# GD32E51x_HD register map
File version: 1.0
CPU: CM33 r0p4, little endian, MPU, FPU, 4 interrupt priority bits
Registers are 32-bit, read-write, reset 0x0 unless marked. A register's access mark holds for its fields unless they carry their own. Offsets are from the block's base; [hi:lo] are bit positions; {n}, {i} and the like mark numbered series.

## TMU
Base 0x40080000
0x00 IDATA0 reset 0x3F800000 — Input data0 register
0x04 IDATA1 reset 0x3F800000 — Input data1 register
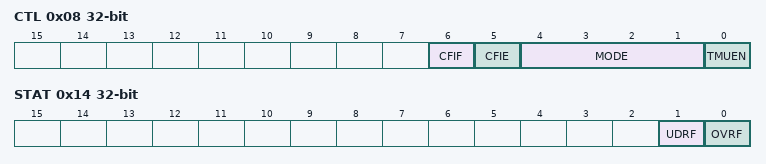
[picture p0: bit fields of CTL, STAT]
0x08 CTL access per field — Control register
  [6] CFIF ro
  [5] CFIE rw
  [4:1] MODE rw — Set the mode of TMU
  [0] TMUEN rw — start TMU module calculation
0x0C DATA0 reset 0x34000000
0x10 DATA1
0x14 STAT ro — Status register
  [1] UDRF — The flag of underflow
  [0] OVRF — The flag of overflow

## WWDGT — Window watchdog timer
Base 0x40002C00
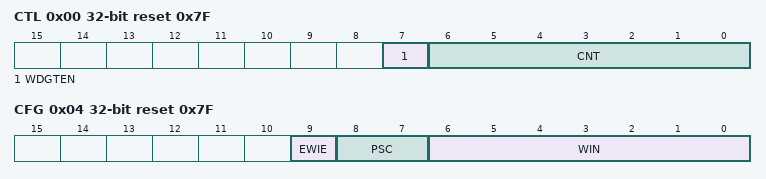
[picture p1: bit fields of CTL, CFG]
0x00 CTL reset 0x7F — Control register
  [7] WDGTEN — Activation bit
  [6:0] CNT — 7-bit counter
0x04 CFG reset 0x7F — Configuration register
  [9] EWIE — Early wakeup interrupt
  [8:7] PSC — Prescaler
  [6:0] WIN — 7-bit window value
0x08 STAT — Status register
  [0] EWIF — Early wakeup interrupt flag

## USBD — Universal serial bus full-speed device interface
Base 0x40005C00
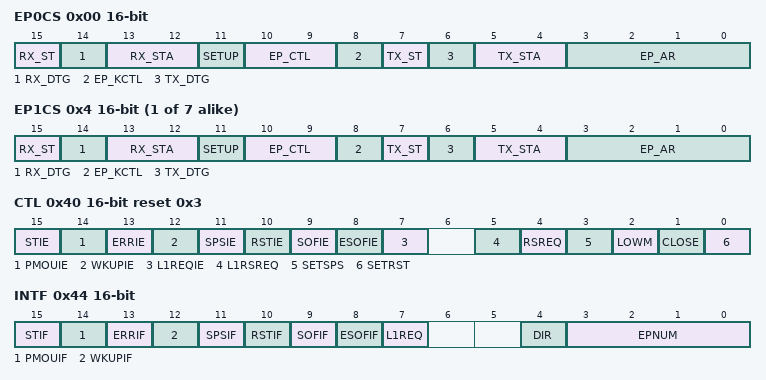
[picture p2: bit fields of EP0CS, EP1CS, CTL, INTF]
0x00 EP0CS 16-bit — endpoint 0 register
  [15] RX_ST — Correct transfer for reception
  [14] RX_DTG — Data Toggle, for reception transfers
  [13:12] RX_STA — Status bits, for reception transfers
  [11] SETUP — Setup transaction completed
  [10:9] EP_CTL — Endpoint type
  [8] EP_KCTL — Endpoint kind
  [7] TX_ST — Correct Transfer for transmission
  [6] TX_DTG — Data PID Toggle, for transmission transfers
  [5:4] TX_STA — Status bits, for transmission transfers
  [3:0] EP_AR — Endpoint address
{0x0+4i} EP{i}CS 16-bit (i=1..7) — endpoint {i} register
  [15] RX_ST — Correct transfer for reception
  [14] RX_DTG — Data Toggle, for reception transfers
  [13:12] RX_STA — Status bits, for reception transfers
  [11] SETUP — Setup transaction completed
  [10:9] EP_CTL — Endpoint type
  [8] EP_KCTL — Endpoint kind
  [7] TX_ST — Correct Transfer for transmission
  [6] TX_DTG — Data Toggle, for transmission transfers
  [5:4] TX_STA — Status bits, for transmission transfers
  [3:0] EP_AR — Endpoint address
0x40 CTL 16-bit reset 0x3 — control register
  [15] STIE — Successful transfer interrupt enable
  [14] PMOUIE — Packet memory area over / underrun interrupt enable
  [13] ERRIE — Error interrupt mask
  [12] WKUPIE — Wakeup interrupt enable
  [11] SPSIE — Suspend mode interrupt mask
  [10] RSTIE — USB reset interrupt mask
  [9] SOFIE — Start of frame interrupt mask
  [8] ESOFIE — Expected start of frame interrupt enable
  [7] L1REQIE — LPM L1 state request interrupt enable
  [5] L1RSREQ — LPM L1 resume request
  [4] RSREQ — Resume request
  [3] SETSPS — Set suspend
  [2] LOWM — Low-power mode
  [1] CLOSE — Close state
  [0] SETRST — Set reset
0x44 INTF 16-bit — interrupt flag register
  [15] STIF — Successful transfer interrupt flag
  [14] PMOUIF — Packet memory area over / underrun interrupt flag
  [13] ERRIF — Error interrupt flag
  [12] WKUPIF — Wakeup interrupt flag
  [11] SPSIF — Suspend mode interrupt flag
  [10] RSTIF — reset interrupt flag
  [9] SOFIF — start of frame interrupt flag
  [8] ESOFIF — Expected start of frame interrupt flag
  [7] L1REQ — LPM L1 transaction is successful
  [4] DIR — Direction of transaction
  [3:0] EPNUM — Endpoint Identifier
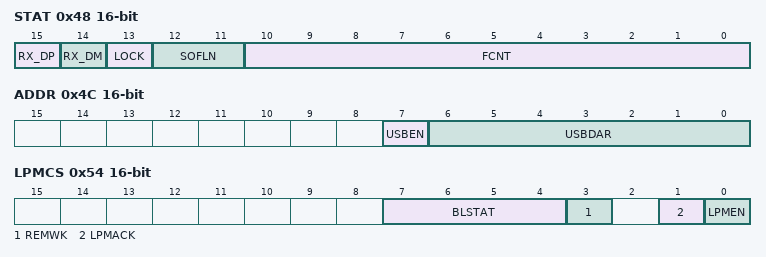
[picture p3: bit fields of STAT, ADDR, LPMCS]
0x48 STAT 16-bit ro — Status register
  [15] RX_DP — Receive data + line status
  [14] RX_DM — Receive data - line status
  [13] LOCK — Locked the USB
  [12:11] SOFLN — Lost SOF number
  [10:0] FCNT — Frame number counter
0x4C ADDR 16-bit — device address register
  [7] USBEN — USB device enable
  [6:0] USBDAR — Device address
0x50 BADDR 16-bit — Buffer address register
  [15:3] BAR — Buffer address
0x54 LPMCS 16-bit — USB LPM control and status register
  [7:4] BLSTAT — bLinkState value
  [3] REMWK — bRemoteWake value
  [1] LPMACK — LPM token acknowledge enable
  [0] LPMEN — LPM support enable
